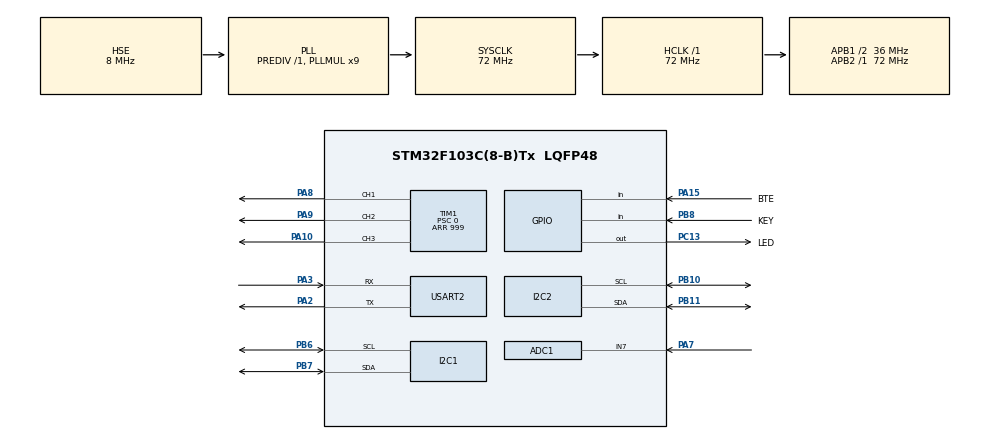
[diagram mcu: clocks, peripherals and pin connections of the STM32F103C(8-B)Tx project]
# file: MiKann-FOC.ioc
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ADC1.Channel-8\#ChannelRegularConversion=ADC_CHANNEL_7
ADC1.ContinuousConvMode=DISABLE
ADC1.NbrOfConversion=1
ADC1.NbrOfConversionFlag=1
ADC1.Rank-8\#ChannelRegularConversion=1
ADC1.SamplingTime-8\#ChannelRegularConversion=ADC_SAMPLETIME_13CYCLES_5
ADC1.master=1
I2C1.I2C_Mode=I2C_Fast
I2C2.I2C_Mode=I2C_Fast
Mcu.Family=STM32F1
Mcu.Name=STM32F103C(8-B)Tx
Mcu.Package=LQFP48
NVIC.ADC1_2_IRQn=true\:0\:0\:false\:false\:true\:true\:true\:true
NVIC.I2C1_ER_IRQn=true\:0\:0\:false\:false\:true\:true\:true\:true
NVIC.I2C1_EV_IRQn=true\:0\:0\:false\:false\:true\:true\:true\:true
NVIC.I2C2_ER_IRQn=true\:0\:0\:false\:false\:true\:true\:true\:true
NVIC.I2C2_EV_IRQn=true\:0\:0\:false\:false\:true\:true\:true\:true
NVIC.PriorityGroup=NVIC_PRIORITYGROUP_4
NVIC.TIM2_IRQn=true\:0\:0\:false\:false\:true\:true\:true\:true
NVIC.USART2_IRQn=true\:0\:0\:false\:false\:true\:true\:true\:true
PA10.Signal=S_TIM1_CH3
PA13.Mode=Serial_Wire
PA13.Signal=SYS_JTMS-SWDIO
PA14.Mode=Serial_Wire
PA14.Signal=SYS_JTCK-SWCLK
PA15.GPIO_Label=BTE
PA15.GPIO_PuPd=GPIO_PULLDOWN
PA15.Signal=GPIO_Input
PA2.Mode=Asynchronous
PA2.Signal=USART2_TX
PA3.Mode=Asynchronous
PA3.Signal=USART2_RX
PA7.Signal=ADCx_IN7
PA8.Signal=S_TIM1_CH1
PA9.Signal=S_TIM1_CH2
PB10.Mode=I2C
PB10.Signal=I2C2_SCL
PB11.Mode=I2C
PB11.Signal=I2C2_SDA
PB6.Mode=I2C
PB6.Signal=I2C1_SCL
PB7.Mode=I2C
PB7.Signal=I2C1_SDA
PB8.GPIO_Label=KEY
PB8.GPIO_PuPd=GPIO_PULLDOWN
PB8.Signal=GPIO_Input
PC13-TAMPER-RTC.GPIO_Label=LED
PC13-TAMPER-RTC.Signal=GPIO_Output
PC14-OSC32_IN.Mode=LSE-External-Oscillator
PC14-OSC32_IN.Signal=RCC_OSC32_IN
PC15-OSC32_OUT.Mode=LSE-External-Oscillator
PC15-OSC32_OUT.Signal=RCC_OSC32_OUT
PD0-OSC_IN.Mode=HSE-External-Oscillator
PD0-OSC_IN.Signal=RCC_OSC_IN
PD1-OSC_OUT.Mode=HSE-External-Oscillator
PD1-OSC_OUT.Signal=RCC_OSC_OUT
ProjectManager.HeapSize=0x200
ProjectManager.StackSize=0x400
ProjectManager.TargetToolchain=Makefile
RCC.ADCPresc=RCC_ADCPCLK2_DIV6
RCC.AHBFreq_Value=72000000
RCC.APB1CLKDivider=RCC_HCLK_DIV2
RCC.APB1Freq_Value=36000000
RCC.APB1TimFreq_Value=72000000
RCC.APB2Freq_Value=72000000
RCC.APB2TimFreq_Value=72000000
RCC.HCLKFreq_Value=72000000
RCC.PLLMUL=RCC_PLL_MUL9
RCC.PLLSourceVirtual=RCC_PLLSOURCE_HSE
RCC.SYSCLKFreq_VALUE=72000000
RCC.SYSCLKSource=RCC_SYSCLKSOURCE_PLLCLK
RCC.USBFreq_Value=72000000
SH.ADCx_IN7.0=ADC1_IN7,IN7
SH.S_TIM1_CH1.0=TIM1_CH1,PWM Generation1 CH1
SH.S_TIM1_CH2.0=TIM1_CH2,PWM Generation2 CH2
SH.S_TIM1_CH3.0=TIM1_CH3,PWM Generation3 CH3
TIM1.AutoReloadPreload=TIM_AUTORELOAD_PRELOAD_ENABLE
TIM1.Channel-PWM\ Generation1\ CH1=TIM_CHANNEL_1
TIM1.Channel-PWM\ Generation2\ CH2=TIM_CHANNEL_2
TIM1.Channel-PWM\ Generation3\ CH3=TIM_CHANNEL_3
TIM1.Period=999
TIM1.Prescaler=0
TIM1.Pulse-PWM\ Generation1\ CH1=0
TIM1.Pulse-PWM\ Generation2\ CH2=0
TIM2.AutoReloadPreload=TIM_AUTORELOAD_PRELOAD_ENABLE
TIM2.Period=99
TIM2.Prescaler=71
USART2.VirtualMode=VM_ASYNC
VP_TIM1_VS_ClockSourceINT.Mode=Internal
VP_TIM2_VS_ClockSourceINT.Mode=Internal
board=custom

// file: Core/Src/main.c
/* USER CODE BEGIN Header */
/**
  ******************************************************************************
  * @file           : main.c
  * @brief          : Main program body
  ******************************************************************************
  * @attention
  *
  * Copyright (c) 2025 STMicroelectronics.
  * All rights reserved.
  *
  * This software is licensed under terms that can be found in the LICENSE file
  * in the root directory of this software component.
  * If no LICENSE file comes with this software, it is provided AS-IS.
  *
  ******************************************************************************
  */
/* USER CODE END Header */
#include "main.h"
#include "adc.h"
#include "i2c.h"
#include "tim.h"
#include "usart.h"
#include "gpio.h"

/* USER CODE BEGIN Includes */
#include "task.h"
/* USER CODE END Includes */

void SystemClock_Config(void);

int main(void)
{

  /* MCU Configuration--------------------------------------------------------*/

  /* Reset of all peripherals, Initializes the Flash interface and the Systick. */
  HAL_Init();

  /* Configure the system clock */
  SystemClock_Config();

  /* Initialize all configured peripherals */
  MX_GPIO_Init();
  MX_I2C1_Init();
  MX_I2C2_Init();
  MX_TIM2_Init();
  MX_TIM1_Init();
  MX_USART2_UART_Init();
  MX_ADC1_Init();
  /* USER CODE BEGIN 2 */
  /* TIM2 以 10 kHz 产生任务调度节拍。 */
  HAL_TIM_Base_Start_IT(&htim2);

  /* TIM1 三路通道输出电机三相 PWM。 */
  HAL_TIM_PWM_Start(&htim1, TIM_CHANNEL_1);
  HAL_TIM_PWM_Start(&htim1, TIM_CHANNEL_2);
  HAL_TIM_PWM_Start(&htim1, TIM_CHANNEL_3);

  // 设置占空比
  // htim1.Instance->CCR1 = 0;

  /* 初始化 OLED 和默认位置控制器。 */
  Task_Init();
  /* USER CODE END 2 */

  /* Infinite loop */
  /* USER CODE BEGIN WHILE */
  while (1)
  {
    /* 每个 TIM2 节拍执行一次任务扫描，具体任务按各自周期到期。 */
    if (GET_TaskExeFlag())
    {
        CLR_TaskExeFlag();
        TaskExe();
    }
    /* USER CODE END WHILE */

  }
}

void SystemClock_Config(void)
{
  RCC_OscInitTypeDef RCC_OscInitStruct = {0};
  RCC_ClkInitTypeDef RCC_ClkInitStruct = {0};
  RCC_PeriphCLKInitTypeDef PeriphClkInit = {0};

  /** Initializes the RCC Oscillators according to the specified parameters
  * in the RCC_OscInitTypeDef structure.
  */
  RCC_OscInitStruct.OscillatorType = RCC_OSCILLATORTYPE_HSE;
  RCC_OscInitStruct.HSEState = RCC_HSE_ON;
  RCC_OscInitStruct.HSEPredivValue = RCC_HSE_PREDIV_DIV1;
  RCC_OscInitStruct.HSIState = RCC_HSI_ON;
  RCC_OscInitStruct.PLL.PLLState = RCC_PLL_ON;
  RCC_OscInitStruct.PLL.PLLSource = RCC_PLLSOURCE_HSE;
  RCC_OscInitStruct.PLL.PLLMUL = RCC_PLL_MUL9;
  if (HAL_RCC_OscConfig(&RCC_OscInitStruct) != HAL_OK)
  {
    Error_Handler();
  }

  /** Initializes the CPU, AHB and APB buses clocks
  */
  RCC_ClkInitStruct.ClockType = RCC_CLOCKTYPE_HCLK|RCC_CLOCKTYPE_SYSCLK
                              |RCC_CLOCKTYPE_PCLK1|RCC_CLOCKTYPE_PCLK2;
  RCC_ClkInitStruct.SYSCLKSource = RCC_SYSCLKSOURCE_PLLCLK;
  RCC_ClkInitStruct.AHBCLKDivider = RCC_SYSCLK_DIV1;
  RCC_ClkInitStruct.APB1CLKDivider = RCC_HCLK_DIV2;
  RCC_ClkInitStruct.APB2CLKDivider = RCC_HCLK_DIV1;

  if (HAL_RCC_ClockConfig(&RCC_ClkInitStruct, FLASH_LATENCY_2) != HAL_OK)
  {
    Error_Handler();
  }
  PeriphClkInit.PeriphClockSelection = RCC_PERIPHCLK_ADC;
  PeriphClkInit.AdcClockSelection = RCC_ADCPCLK2_DIV6;
  if (HAL_RCCEx_PeriphCLKConfig(&PeriphClkInit) != HAL_OK)
  {
    Error_Handler();
  }
}

void Error_Handler(void)
{
  __disable_irq();
  while (1)
  {
  }
}
